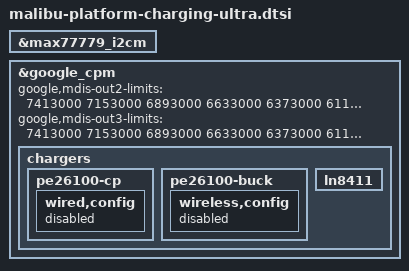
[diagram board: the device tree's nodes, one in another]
// SPDX-License-Identifier: GPL-2.0-only
/*
 * Battery device tree entries specific to mbu ultra charging devices
 *
 * Copyright 2025 Google LLC
 *
 */

&max77779_i2cm {
	#include "malibu-charge-pump-ln8411.dtsi"
};

&google_cpm {
	google,mdis-out2-limits =
	<7413000 7153000 6893000 6633000 6373000 6113000 5853000 5593000 5333000
	 5073000 4813000 4553000 4293000 4033000 3773000 3513000 3253000 2993000
	 2733000 2473000 2213000 1953000 1693000 1433000 1173000 1000000
	 4800000 4600000 4400000 4200000 4000000 3800000 3600000 3400000 3200000
	 3000000 2800000 2600000 2400000 2200000 2000000 1800000 1600000 1400000
	 1200000 1000000 900000  800000  700000  600000  500000  400000>;

	google,mdis-out3-limits =
	<7413000 7153000 6893000 6633000 6373000 6113000 5853000 5593000 5333000
	 5073000 4813000 4553000 4293000 4033000 3773000 3513000 3253000 2993000
	 2733000 2473000 2213000 1953000 1693000 1433000 1173000 1000000
	 4800000 4600000 4400000 4200000 4000000 3800000 3600000 3400000 3200000
	 3000000 2800000 2600000 2400000 2200000 2000000 1800000 1600000 1400000
	 1200000 1000000 900000  800000  700000  600000  500000  400000>;

	chargers {
		pe26100-cp {
			wired,config {
				status = "disabled";
			};
		};

		pe26100-buck {
			wireless,config {
				status = "disabled";
			};
		};

		ln8411 {
			status = "okay";
		};
	};
};
